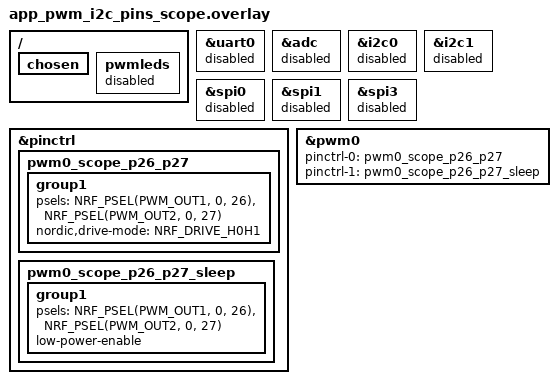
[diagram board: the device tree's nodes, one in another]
/*
 * pwm0 OUT1 → P0.26 (Arduino D14), OUT2 → P0.27 (Arduino D15 / VitaBand I²C pads).
 * Disables TWIM/SPI that share those pins so PWM owns the pads.
 *
 * nRF Connect / west:
 *   -DCONF_FILE=prj_pwm_i2c_pins_scope.conf -DDTC_OVERLAY_FILE=app_pwm_i2c_pins_scope.overlay
 */

#include <zephyr/dt-bindings/pinctrl/nrf-pinctrl.h>

/ {
	chosen {
		/delete-property/ zephyr,console;
		/delete-property/ zephyr,shell-uart;
		/delete-property/ zephyr,uart-mcumgr;
		/delete-property/ zephyr,bt-mon-uart;
		/delete-property/ zephyr,bt-c2h-uart;
	};

	pwmleds {
		status = "disabled";
	};
};

&uart0 {
	status = "disabled";
};

&adc {
	status = "disabled";
};

&i2c0 {
	status = "disabled";
};

&i2c1 {
	status = "disabled";
};

&spi0 {
	status = "disabled";
};

&spi1 {
	status = "disabled";
};

&spi3 {
	status = "disabled";
};

&pinctrl {
	pwm0_scope_p26_p27: pwm0_scope_p26_p27 {
		group1 {
			psels = <NRF_PSEL(PWM_OUT1, 0, 26)>,
				<NRF_PSEL(PWM_OUT2, 0, 27)>;
			nordic,drive-mode = <NRF_DRIVE_H0H1>;
		};
	};

	pwm0_scope_p26_p27_sleep: pwm0_scope_p26_p27_sleep {
		group1 {
			psels = <NRF_PSEL(PWM_OUT1, 0, 26)>,
				<NRF_PSEL(PWM_OUT2, 0, 27)>;
			low-power-enable;
		};
	};
};

&pwm0 {
	status = "okay";
	pinctrl-0 = <&pwm0_scope_p26_p27>;
	pinctrl-1 = <&pwm0_scope_p26_p27_sleep>;
	pinctrl-names = "default", "sleep";
};
